# nrf52 register map
Vendor: Nordic Semiconductor; Series: nrf52; File version: 1
CPU: CM4 r0p1, little endian, MPU, FPU, 3 interrupt priority bits
Registers are 32-bit, read-write, reset 0x0 unless marked. A register's access mark holds for its fields unless they carry their own. Offsets are from the block's base; [hi:lo] are bit positions; lines under a group give offsets from that group; {n}, {i} and the like mark numbered series.

## PPI — Programmable Peripheral Interconnect
Base 0x4001F000
{0x0+8i} TASKS_CHG[{i}] (i=0..5) group — Channel group tasks
  0x00 EN wo — Description cluster[0]: Enable channel group 0
  0x04 DIS wo — Description cluster[0]: Disable channel group 0
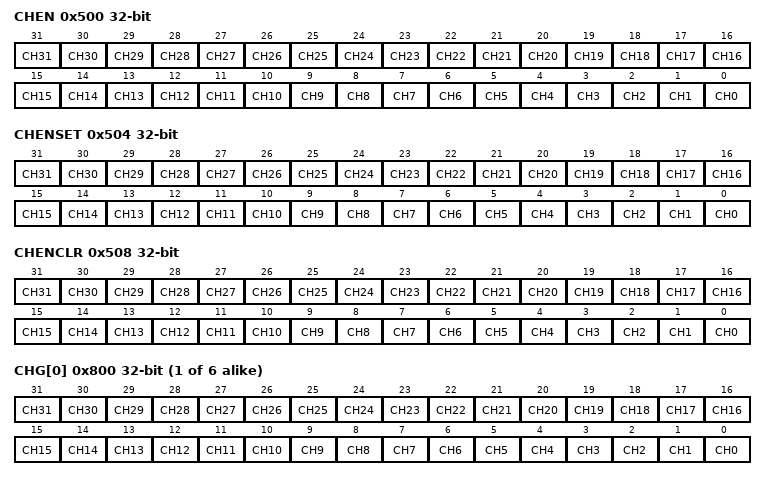
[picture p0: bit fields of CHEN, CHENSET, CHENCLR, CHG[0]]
0x500 CHEN — Channel enable register
  [all] fields
    0=Disabled (Disable channel); 1=Enabled (Enable channel)
  [n] CH{n} (n=0..31) — Enable or disable channel {n}
0x504 CHENSET write-1-sets — Channel enable set register
  [all] fields
    on read: 0=Disabled (Read: channel disabled); 1=Enabled (Read: channel enabled) | on write: 1=Set (Write: Enable channel)
  [n] CH{n} (n=0..31) — Channel {n} enable set register. Writing '0' has no effect
0x508 CHENCLR write-1-clears — Channel enable clear register
  [all] fields
    on read: 0=Disabled (Read: channel disabled); 1=Enabled (Read: channel enabled) | on write: 1=Clear (Write: disable channel)
  [n] CH{n} (n=0..31) — Channel {n} enable clear register. Writing '0' has no effect
{0x510+8i} CH[{i}] (i=0..19) group — PPI Channel
  0x00 EEP — Description cluster[0]: Channel 0 event end-point
    [31:0] EEP — Pointer to event register. Accepts only addresses to registers from the Event group.
  0x04 TEP — Description cluster[0]: Channel 0 task end-point
    [31:0] TEP — Pointer to task register. Accepts only addresses to registers from the Task group.
{0x800+4i} CHG[{i}] (i=0..5) — Description collection[0]: Channel group 0
  [all] fields
    0=Excluded; 1=Included
  [n] CH{n} (n=0..31) — Include or exclude channel {n}
{0x910+4i} FORK[{i}] (i=0..31) group
  0x00 TEP — Description cluster[0]: Channel 0 task end-point
    [31:0] TEP — Pointer to task register

## P0 — GPIO Port 1
Base 0x50000000
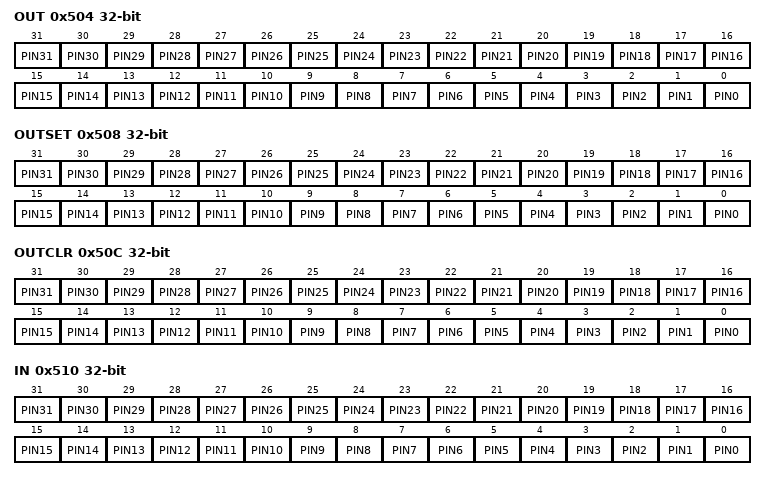
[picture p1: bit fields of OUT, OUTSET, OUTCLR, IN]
0x504 OUT — Write GPIO port
  [all] fields
    0=Low (Pin driver is low); 1=High (Pin driver is high)
  [n] PIN{n} (n=0..31)
0x508 OUTSET write-1-sets — Set individual bits in GPIO port
  [all] fields
    on read: 0=Low (Read: pin driver is low); 1=High (Read: pin driver is high) | on write: 1=Set (Write: writing a '1' sets the pin high; writing a '0' has no effect)
  [n] PIN{n} (n=0..31)
0x50C OUTCLR write-1-clears — Clear individual bits in GPIO port
  [all] fields
    on read: 0=Low (Read: pin driver is low); 1=High (Read: pin driver is high) | on write: 1=Clear (Write: writing a '1' sets the pin low; writing a '0' has no effect)
  [n] PIN{n} (n=0..31)
0x510 IN ro — Read GPIO port
  [all] fields
    0=Low (Pin input is low); 1=High (Pin input is high)
  [n] PIN{n} (n=0..31)
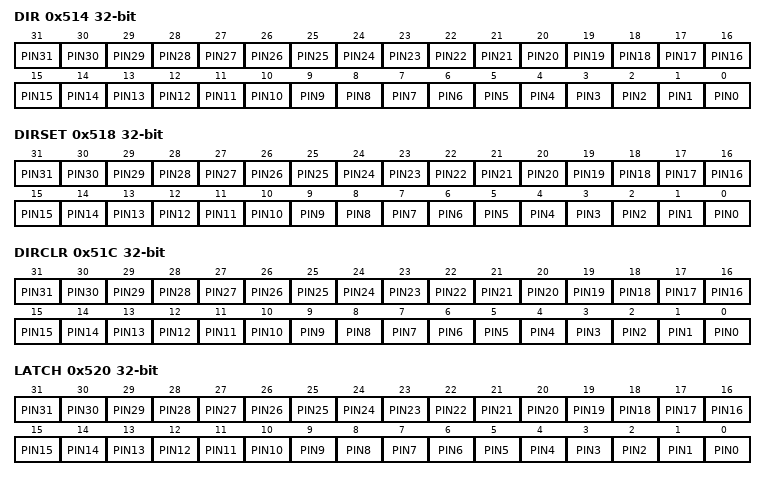
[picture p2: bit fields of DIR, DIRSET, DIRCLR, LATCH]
0x514 DIR — Direction of GPIO pins
  [all] fields
    0=Input (Pin set as input); 1=Output (Pin set as output)
  [n] PIN{n} (n=0..31)
0x518 DIRSET write-1-sets
  [all] fields
    on read: 0=Input (Read: pin set as input); 1=Output (Read: pin set as output) | on write: 1=Set (Write: writing a '1' sets pin to output; writing a '0' has no effect)
  [n] PIN{n} (n=0..31) — Set as output pin {n}
0x51C DIRCLR write-1-clears — DIR clear register
  [all] fields
    on read: 0=Input (Read: pin set as input); 1=Output (Read: pin set as output) | on write: 1=Clear (Write: writing a '1' sets pin to input; writing a '0' has no effect)
  [n] PIN{n} (n=0..31) — Set as input pin {n}
0x520 LATCH — Latch register indicating what GPIO pins that have met the criteria set in the PIN_CNF[n].SENSE registers
  [all] fields
    0=NotLatched (Criteria has not been met); 1=Latched (Criteria has been met)
  [n] PIN{n} (n=0..31) — Status on whether PIN{n} has met criteria set in PIN_CNF{n}.SENSE register. Write '1' to clear.
0x524 DETECTMODE — Select between default DETECT signal behaviour and LDETECT mode
  [0] DETECTMODE
    0=Default (DETECT directly connected to PIN DETECT signals); 1=LDETECT (Use the latched LDETECT behaviour)
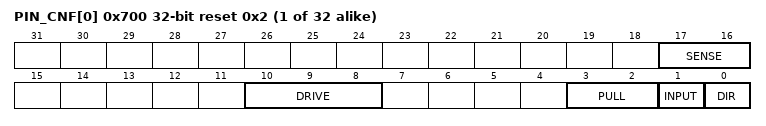
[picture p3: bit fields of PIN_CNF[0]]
{0x700+4i} PIN_CNF[{i}] (i=0..31) reset 0x2 — Description collection[0]: Configuration of GPIO pins
  [17:16] SENSE — Pin sensing mechanism
    0=Disabled; 2=High (Sense for high level); 3=Low (Sense for low level)
  [10:8] DRIVE — Drive configuration
    0=S0S1 (Standard '0', standard '1'); 1=H0S1 (High drive '0', standard '1'); 2=S0H1 (Standard '0', high drive '1'); 3=H0H1 (High drive '0', high 'drive '1''); 4=D0S1 (Disconnect '0' standard '1' (normally used for wired-or connections)); 5=D0H1 (Disconnect '0', high drive '1' (normally used for wired-or connections)); 6=S0D1 (Standard '0'. disconnect '1' (normally used for wired-and connections)); 7=H0D1 (High drive '0', disconnect '1' (normally used for wired-and connections))
  [3:2] PULL — Pull configuration
    0=Disabled (No pull); 1=Pull down on pin; 3=Pull up on pin
  [1] INPUT — Connect or disconnect input buffer
    0=Connect input buffer; 1=Disconnect input buffer
  [0] DIR — Pin direction. Same physical register as DIR register
    0=Input (Configure pin as an input pin); 1=Output (Configure pin as an output pin)
